AUTOSAR XML (schema 4-2-2)
package /Components
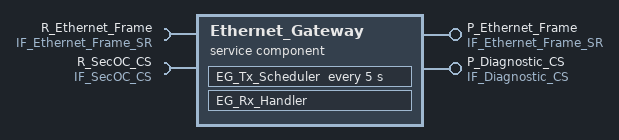
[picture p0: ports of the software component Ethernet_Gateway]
  service sw component type Ethernet_Gateway
    provide port P_Ethernet_Frame: provided-interface=IF_Ethernet_Frame_SR
    provide port P_Diagnostic_CS: provided-interface=IF_Diagnostic_CS
    require port R_Ethernet_Frame: required-interface=IF_Ethernet_Frame_SR
    require port R_SecOC_CS: required-interface=IF_SecOC_CS
    behavior Ethernet_Gateway_InternalBehavior
      data received event EG_FrameRx: start-on-event=EG_Rx_Handler
      init event EG_InitEvent: start-on-event=EG_Tx_Scheduler
      timing event EG_TxSchedule: start-on-event=EG_Tx_Scheduler, period=5
      runnable EG_Rx_Handler
        data-receive-point-by-values:
          access RX_Ethernet_Frame: accessed-variable=R_Ethernet_Frame.ethernet_frame
        data-send-points:
          access TX_Ethernet_Frame_FromRx: accessed-variable=P_Ethernet_Frame.ethernet_frame
        async call SecOC_Verify_Async: operation=R_SecOC_CS.Verify_Auth_Tag_Op, timeout=5
      runnable EG_Tx_Scheduler: minimum-start-interval=5
        data-receive-point-by-values:
          access RX_Link_Status: accessed-variable=R_Ethernet_Frame.link_status
        data-send-points:
          access TX_Ethernet_Frame: accessed-variable=P_Ethernet_Frame.ethernet_frame
        sync call SecOC_Generate_Sync: operation=R_SecOC_CS.Generate_Auth_Tag_Op, timeout=2, called-from-within-exclusive-area=EA_TxArea
